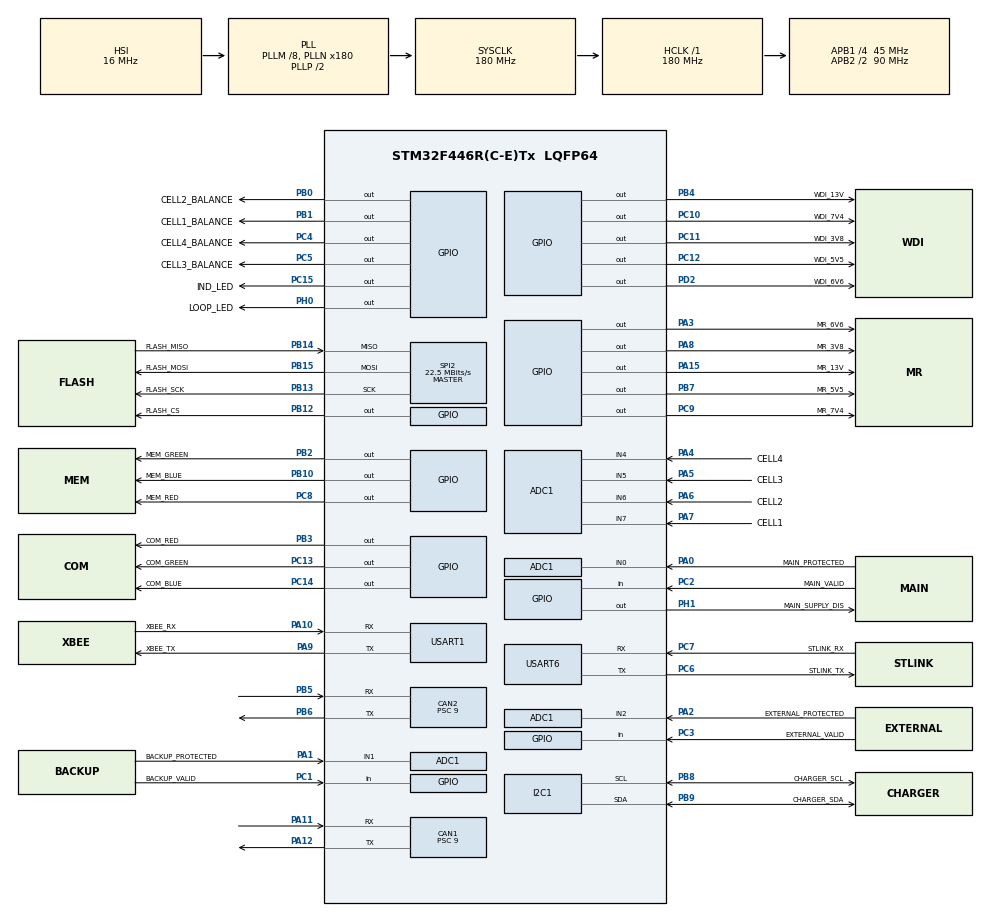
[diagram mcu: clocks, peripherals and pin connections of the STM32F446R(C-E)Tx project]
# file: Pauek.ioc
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Dma.USART1_TX.2.Direction=DMA_MEMORY_TO_PERIPH
NVIC.CAN1_RX1_IRQn=true\:5\:0\:true\:false\:true\:true\:true
PH0-OSC_IN.GPIO_PuPd=GPIO_NOPULL
PH0-OSC_IN.Signal=GPIO_Output
PC10.GPIO_PuPd=GPIO_NOPULL
PH0-OSC_IN.PinState=GPIO_PIN_RESET
PB10.GPIO_PuPd=GPIO_NOPULL
SPI2.VirtualType=VM_MASTER
PA10.GPIO_PuPd=GPIO_PULLUP
ADC1.SamplingTime-6\#ChannelRegularConversion=ADC_SAMPLETIME_56CYCLES
PC12.Signal=GPIO_Output
PB14.GPIO_Label=FLASH_MISO
PA3.GPIO_PuPd=GPIO_NOPULL
PC6.GPIO_Label=STLINK_TX
PA6.GPIO_Label=CELL2
PA3.GPIO_Speed=GPIO_SPEED_FREQ_LOW
PB13.Signal=SPI2_SCK
PC15-OSC32_OUT.GPIO_Label=IND_LED
PB3.GPIO_Speed=GPIO_SPEED_FREQ_LOW
RCC.SYSCLKSource=RCC_SYSCLKSOURCE_PLLCLK
PA6.GPIO_Mode=GPIO_MODE_ANALOG
ADC1.Channel-5\#ChannelRegularConversion=ADC_CHANNEL_6
PC13.GPIO_ModeDefaultOutputPP=GPIO_MODE_OUTPUT_PP
PB3.PinState=GPIO_PIN_RESET
NVIC.CAN1_TX_IRQn=true\:5\:0\:true\:false\:true\:true\:true
RCC.APB2TimFreq_Value=180000000
PB6.Signal=CAN2_TX
Dma.ADC1.0.Direction=DMA_PERIPH_TO_MEMORY
ADC1.Channel-2\#ChannelRegularConversion=ADC_CHANNEL_2
PC7.Signal=USART6_RX
ADC1.InjNumberOfConversion=0
PB12.PinState=GPIO_PIN_RESET
PB6.Mode=Slave
PC3.Signal=GPIO_Input
PA1.GPIO_PuPd=GPIO_NOPULL
Dma.ADC1.0.MemDataAlignment=DMA_MDATAALIGN_HALFWORD
Dma.USART1_RX.1.PeriphDataAlignment=DMA_PDATAALIGN_BYTE
NVIC.TIM8_TRG_COM_TIM14_IRQn=true\:5\:0\:true\:false\:true\:true\:true
PB2.Signal=GPIO_Output
PB12.GPIO_ModeDefaultOutputPP=GPIO_MODE_OUTPUT_PP
PC1.GPIO_PuPd=GPIO_NOPULL
PB12.GPIO_Label=FLASH_CS
PC4.GPIO_Label=CELL4_BALANCE
PB1.GPIO_Speed=GPIO_SPEED_FREQ_LOW
PB14.Mode=Full_Duplex_Master
PA5.GPIO_PuPd=GPIO_NOPULL
PB1.GPIO_Label=CELL1_BALANCE
Dma.ADC1.0.PeriphInc=DMA_PINC_DISABLE
PA0-WKUP.GPIO_Mode=GPIO_MODE_ANALOG
SPI2.CalculateBaudRate=22.5 MBits/s
PC11.GPIO_Speed=GPIO_SPEED_FREQ_LOW
PA8.Signal=GPIO_Output
PA8.GPIO_ModeDefaultOutputPP=GPIO_MODE_OUTPUT_OD
PC15-OSC32_OUT.PinState=GPIO_PIN_RESET
PC10.PinState=GPIO_PIN_RESET
Dma.USART1_TX.2.MemDataAlignment=DMA_MDATAALIGN_BYTE
PB2.GPIO_PuPd=GPIO_NOPULL
ADC1.SamplingTime-0\#ChannelRegularConversion=ADC_SAMPLETIME_56CYCLES
PB7.PinState=GPIO_PIN_SET
PC14-OSC32_IN.GPIO_Speed=GPIO_SPEED_FREQ_LOW
Dma.USART1_RX.1.Mode=DMA_NORMAL
PC10.GPIO_ModeDefaultOutputPP=GPIO_MODE_OUTPUT_PP
CAN1.Prescaler=9
Mcu.Package=LQFP64
PB9.Signal=I2C1_SDA
PB1.Signal=GPIO_Output
NVIC.TimeBase=TIM8_UP_TIM13_IRQn
SPI2.Mode=SPI_MODE_MASTER
NVIC.TimeBaseIP=TIM13
PA10.Signal=USART1_RX
PC6.GPIO_PuPd=GPIO_PULLUP
PC8.GPIO_Speed=GPIO_SPEED_FREQ_LOW
Dma.USART1_RX.1.PeriphInc=DMA_PINC_DISABLE
RCC.APB2CLKDivider=RCC_HCLK_DIV2
NVIC.DMA2_Stream2_IRQn=true\:5\:0\:true\:false\:true\:false\:true
PC2.GPIO_Mode=GPIO_MODE_INPUT
RCC.APB1TimFreq_Value=90000000
Dma.ADC1.0.FIFOMode=DMA_FIFOMODE_DISABLE
PB0.GPIO_ModeDefaultOutputPP=GPIO_MODE_OUTPUT_PP
PB13.Mode=Full_Duplex_Master
VP_TIM14_VS_ClockSourceINT.Mode=Enable_Timer
PC12.GPIO_PuPd=GPIO_NOPULL
NVIC.USART1_IRQn=true\:5\:0\:true\:false\:true\:true\:true
PB2.GPIO_ModeDefaultOutputPP=GPIO_MODE_OUTPUT_PP
PA4.GPIO_Label=CELL4
PC6.GPIO_Speed=GPIO_SPEED_FREQ_VERY_HIGH
PA8.GPIO_Speed=GPIO_SPEED_FREQ_LOW
ADC1.EOCSelection=ADC_EOC_SEQ_CONV
ADC1.Rank-4\#ChannelRegularConversion=5
CAN1.CalculateTimeQuantum=200.0
PA2.GPIO_Mode=GPIO_MODE_ANALOG
PB7.GPIO_PuPd=GPIO_NOPULL
Dma.USART1_RX.1.Instance=DMA2_Stream2
NVIC.CAN2_TX_IRQn=true\:5\:0\:true\:false\:true\:true\:true
Dma.ADC1.0.Instance=DMA2_Stream0
PA3.GPIO_ModeDefaultOutputPP=GPIO_MODE_OUTPUT_OD
Dma.USART1_RX.1.MemDataAlignment=DMA_MDATAALIGN_BYTE
ADC1.Rank-0\#ChannelRegularConversion=1
Dma.USART1_TX.2.MemInc=DMA_MINC_ENABLE
PA1.GPIO_Mode=GPIO_MODE_ANALOG
PC4.PinState=GPIO_PIN_RESET
PD2.GPIO_PuPd=GPIO_NOPULL
SH.ADCx_IN6.0=ADC1_IN6,IN6
PA9.GPIO_Label=XBEE_TX
PC13.Signal=GPIO_Output
PC2.Signal=GPIO_Input
PC6.Signal=USART6_TX
PC9.PinState=GPIO_PIN_SET
PC12.GPIO_ModeDefaultOutputPP=GPIO_MODE_OUTPUT_PP
RCC.APB1CLKDivider=RCC_HCLK_DIV4
PC14-OSC32_IN.Signal=GPIO_Output
NVIC.CAN2_RX1_IRQn=true\:5\:0\:true\:false\:true\:true\:true
PA0-WKUP.GPIO_Label=MAIN_PROTECTED
PA0-WKUP.Signal=ADCx_IN0
PB8.GPIO_Label=CHARGER_SCL
PA8.GPIO_Label=MR_3V8
PC12.PinState=GPIO_PIN_RESET
SH.ADCx_IN7.0=ADC1_IN7,IN7
PC6.Mode=Asynchronous
Dma.ADC1.0.Priority=DMA_PRIORITY_LOW
PA9.Signal=USART1_TX
VP_TIM8_VS_ClockSourceINT.Mode=Internal
PB4.GPIO_PuPd=GPIO_NOPULL
PC7.GPIO_PuPd=GPIO_PULLUP
PH1-OSC_OUT.GPIO_PuPd=GPIO_NOPULL
PB10.Signal=GPIO_Output
PB14.Signal=SPI2_MISO
PA5.Signal=ADCx_IN5
Dma.USART1_RX.1.FIFOMode=DMA_FIFOMODE_DISABLE
Dma.USART1_TX.2.FIFOMode=DMA_FIFOMODE_DISABLE
PB4.GPIO_Label=WDI_13V
PB15.GPIO_Label=FLASH_MOSI
PA1.GPIO_Label=BACKUP_PROTECTED
PC9.GPIO_PuPd=GPIO_NOPULL
SH.ADCx_IN4.0=ADC1_IN4,IN4
PC15-OSC32_OUT.GPIO_PuPd=GPIO_NOPULL
PH1-OSC_OUT.GPIO_Label=MAIN_SUPPLY_DIS
PC6.GPIO_Mode=GPIO_MODE_AF_PP
PC11.GPIO_ModeDefaultOutputPP=GPIO_MODE_OUTPUT_PP
ADC1.DMAContinuousRequests=ENABLE
PA13.Mode=Serial_Wire
TIM14.Prescaler=8900
ADC1.ExternalTrigConv=ADC_EXTERNALTRIGCONV_T8_TRGO
TIM8.Period=999
PC7.GPIO_Label=STLINK_RX
PC8.GPIO_PuPd=GPIO_NOPULL
PA4.Signal=ADCx_IN4
ADC1.SamplingTime-1\#ChannelRegularConversion=ADC_SAMPLETIME_56CYCLES
PB5.Signal=CAN2_RX
ADC1.master=1
PA5.GPIO_Label=CELL3
TIM8.TIM_MasterOutputTrigger=TIM_TRGO_UPDATE
PC12.GPIO_Label=WDI_5V5
USART1.VirtualMode=VM_ASYNC
ADC1.Rank-1\#ChannelRegularConversion=2
PA11.Signal=CAN1_RX
ProjectManager.HeapSize=0x200
NVIC.CAN2_SCE_IRQn=true\:5\:0\:true\:false\:true\:true\:true
ADC1.SamplingTime-5\#ChannelRegularConversion=ADC_SAMPLETIME_56CYCLES
NVIC.TIM8_UP_TIM13_IRQn=true\:0\:0\:true\:false\:true\:false\:true
PH1-OSC_OUT.PinState=GPIO_PIN_RESET
SH.ADCx_IN5.0=ADC1_IN5,IN5
PC9.GPIO_Speed=GPIO_SPEED_FREQ_LOW
NVIC.PriorityGroup=NVIC_PRIORITYGROUP_4
PC5.GPIO_Speed=GPIO_SPEED_FREQ_LOW
Dma.USART1_TX.2.Instance=DMA2_Stream7
PB8.Mode=I2C
PC3.GPIO_Label=EXTERNAL_VALID
PA0-WKUP.GPIO_PuPd=GPIO_NOPULL
PA3.PinState=GPIO_PIN_SET
PC14-OSC32_IN.GPIO_PuPd=GPIO_NOPULL
Dma.USART1_RX.1.Direction=DMA_PERIPH_TO_MEMORY
PB1.GPIO_ModeDefaultOutputPP=GPIO_MODE_OUTPUT_PP
PD2.Signal=GPIO_Output
PB12.GPIO_PuPd=GPIO_NOPULL
PB0.Signal=GPIO_Output
ADC1.Rank-5\#ChannelRegularConversion=6
PC1.Signal=GPIO_Input
PD2.GPIO_Label=WDI_6V6
NVIC.CAN1_RX0_IRQn=true\:5\:0\:true\:false\:true\:true\:true
Mcu.Family=STM32F4
PC3.GPIO_Mode=GPIO_MODE_INPUT
PA2.GPIO_PuPd=GPIO_NOPULL
PB10.PinState=GPIO_PIN_RESET
RCC.CortexFreq_Value=180000000
PD2.GPIO_ModeDefaultOutputPP=GPIO_MODE_OUTPUT_PP
NVIC.CAN2_RX0_IRQn=true\:5\:0\:true\:false\:true\:true\:true
PB10.GPIO_Speed=GPIO_SPEED_FREQ_LOW
ADC1.ContinuousConvMode=DISABLE
SH.ADCx_IN2.0=ADC1_IN2,IN2
PC10.Signal=GPIO_Output
PB2.GPIO_Speed=GPIO_SPEED_FREQ_LOW
PA7.GPIO_Mode=GPIO_MODE_ANALOG
PA11.Mode=Master
PD2.GPIO_Speed=GPIO_SPEED_FREQ_LOW
PB0.GPIO_Label=CELL2_BALANCE
PC10.GPIO_Speed=GPIO_SPEED_FREQ_LOW
PC13.GPIO_Label=COM_GREEN
PB13.GPIO_Label=FLASH_SCK
PB15.Signal=SPI2_MOSI
ProjectManager.StackSize=0x400
PC8.PinState=GPIO_PIN_RESET
PH1-OSC_OUT.GPIO_Speed=GPIO_SPEED_FREQ_LOW
PH1-OSC_OUT.GPIO_ModeDefaultOutputPP=GPIO_MODE_OUTPUT_PP
NVIC.ADC_IRQn=true\:5\:0\:true\:false\:true\:true\:true
PA15.GPIO_Label=MR_13V
PC11.GPIO_PuPd=GPIO_NOPULL
PB10.GPIO_ModeDefaultOutputPP=GPIO_MODE_OUTPUT_PP
PA12.Signal=CAN1_TX
PB0.PinState=GPIO_PIN_RESET
ADC1.Channel-3\#ChannelRegularConversion=ADC_CHANNEL_4
PB1.GPIO_PuPd=GPIO_NOPULL
RCC.HCLKFreq_Value=180000000
PH0-OSC_IN.GPIO_ModeDefaultOutputPP=GPIO_MODE_OUTPUT_PP
NVIC.DMA2_Stream0_IRQn=true\:5\:0\:true\:false\:true\:false\:true
NVIC.CAN1_SCE_IRQn=true\:5\:0\:true\:false\:true\:true\:true
Dma.USART1_RX.1.MemInc=DMA_MINC_ENABLE
RCC.AHBFreq_Value=180000000
PH0-OSC_IN.GPIO_Label=LOOP_LED
PA9.GPIO_Mode=GPIO_MODE_AF_PP
PC1.GPIO_Mode=GPIO_MODE_INPUT
ADC1.Channel-0\#ChannelRegularConversion=ADC_CHANNEL_0
PA4.GPIO_PuPd=GPIO_NOPULL
PC4.GPIO_Speed=GPIO_SPEED_FREQ_LOW
ADC1.SamplingTime-4\#ChannelRegularConversion=ADC_SAMPLETIME_56CYCLES
ADC1.Channel-6\#ChannelRegularConversion=ADC_CHANNEL_7
PA6.GPIO_PuPd=GPIO_NOPULL
PB3.GPIO_PuPd=GPIO_NOPULL
ADC1.Rank-2\#ChannelRegularConversion=3
PA14.Mode=Serial_Wire
CAN2.Prescaler=9
PC11.GPIO_Label=WDI_3V8
PB5.Mode=Slave
PA10.GPIO_Label=XBEE_RX
PC13.GPIO_PuPd=GPIO_NOPULL
PC7.GPIO_Mode=GPIO_MODE_AF_PP
Dma.USART1_TX.2.PeriphDataAlignment=DMA_PDATAALIGN_BYTE
PB7.Signal=GPIO_Output
SH.ADCx_IN0.0=ADC1_IN0,IN0
PA15.GPIO_ModeDefaultOutputPP=GPIO_MODE_OUTPUT_OD
PB1.PinState=GPIO_PIN_RESET
PB7.GPIO_Label=MR_5V5
PA6.Signal=ADCx_IN6
NVIC.DMA2_Stream7_IRQn=true\:5\:0\:true\:false\:true\:false\:true
CAN2.BS1=CAN_BS1_6TQ
CAN2.BS2=CAN_BS2_6TQ
PC14-OSC32_IN.PinState=GPIO_PIN_RESET
USART6.VirtualMode=VM_ASYNC
PA2.GPIO_Label=EXTERNAL_PROTECTED
PC8.GPIO_ModeDefaultOutputPP=GPIO_MODE_OUTPUT_PP
PA15.Signal=GPIO_Output
PA10.GPIO_Speed=GPIO_SPEED_FREQ_VERY_HIGH
TIM8.Prescaler=8999
SH.ADCx_IN1.0=ADC1_IN1,IN1
PC15-OSC32_OUT.GPIO_ModeDefaultOutputPP=GPIO_MODE_OUTPUT_PP
Dma.Request2=USART1_TX
PC14-OSC32_IN.GPIO_ModeDefaultOutputPP=GPIO_MODE_OUTPUT_PP
Dma.Request1=USART1_RX
PC13.GPIO_Speed=GPIO_SPEED_FREQ_LOW
PC14-OSC32_IN.GPIO_Label=COM_BLUE
SPI2.Direction=SPI_DIRECTION_2LINES
PC15-OSC32_OUT.GPIO_Speed=GPIO_SPEED_FREQ_LOW
PC5.Signal=GPIO_Output
Dma.USART1_RX.1.Priority=DMA_PRIORITY_LOW
PC4.GPIO_ModeDefaultOutputPP=GPIO_MODE_OUTPUT_PP
ADC1.Rank-6\#ChannelRegularConversion=7
Dma.Request0=ADC1
PB4.PinState=GPIO_PIN_RESET
PC2.GPIO_Label=MAIN_VALID
PC13.PinState=GPIO_PIN_RESET
PA8.PinState=GPIO_PIN_SET
PB4.Signal=GPIO_Output
PB4.GPIO_ModeDefaultOutputPP=GPIO_MODE_OUTPUT_PP
PA3.Signal=GPIO_Output
PB7.GPIO_Speed=GPIO_SPEED_FREQ_LOW
PB3.GPIO_Label=COM_RED
PB9.GPIO_Label=CHARGER_SDA
ADC1.Channel-4\#ChannelRegularConversion=ADC_CHANNEL_5
PA10.Mode=Asynchronous
PC10.GPIO_Label=WDI_7V4
PC9.GPIO_Label=MR_7V4
PC4.GPIO_PuPd=GPIO_NOPULL
PC11.Signal=GPIO_Output
PC8.Signal=GPIO_Output
PC4.Signal=GPIO_Output
PC5.GPIO_PuPd=GPIO_NOPULL
PA9.GPIO_PuPd=GPIO_PULLUP
ADC1.SamplingTime-2\#ChannelRegularConversion=ADC_SAMPLETIME_56CYCLES
NVIC.USART6_IRQn=true\:5\:0\:true\:false\:true\:true\:true
PA10.GPIO_Mode=GPIO_MODE_AF_PP
PB0.GPIO_Speed=GPIO_SPEED_FREQ_LOW
PC8.GPIO_Label=MEM_RED
PA13.Signal=SYS_JTMS-SWDIO
Dma.ADC1.0.PeriphDataAlignment=DMA_PDATAALIGN_HALFWORD
PA9.Mode=Asynchronous
CAN1.BS2=CAN_BS2_6TQ
CAN1.BS1=CAN_BS1_6TQ
ProjectManager.TargetToolchain=SW4STM32
PB10.GPIO_Label=MEM_BLUE
Dma.ADC1.0.Mode=DMA_CIRCULAR
PB9.Mode=I2C
ADC1.Channel-1\#ChannelRegularConversion=ADC_CHANNEL_1
RCC.USBFreq_Value=180000000
PC15-OSC32_OUT.Signal=GPIO_Output
PA1.Signal=ADCx_IN1
PA7.GPIO_PuPd=GPIO_NOPULL
PB12.GPIO_Speed=GPIO_SPEED_FREQ_LOW
PD2.PinState=GPIO_PIN_RESET
board=custom
PC7.GPIO_Speed=GPIO_SPEED_FREQ_VERY_HIGH
RCC.VCOOutputFreq_Value=360000000
PB15.Mode=Full_Duplex_Master
PA4.GPIO_Mode=GPIO_MODE_ANALOG
PA15.PinState=GPIO_PIN_SET
PB4.GPIO_Speed=GPIO_SPEED_FREQ_LOW
RCC.APB2Freq_Value=90000000
PC11.PinState=GPIO_PIN_RESET
VP_SYS_VS_tim13.Mode=TIM13
PB7.GPIO_ModeDefaultOutputPP=GPIO_MODE_OUTPUT_OD
PC9.GPIO_ModeDefaultOutputPP=GPIO_MODE_OUTPUT_OD
Dma.USART1_TX.2.Priority=DMA_PRIORITY_LOW
PC1.GPIO_Label=BACKUP_VALID
CAN2.CalculateTimeQuantum=200.0
PH1-OSC_OUT.Signal=GPIO_Output
PC2.GPIO_PuPd=GPIO_NOPULL
ADC1.NbrOfConversion=7
Mcu.Name=STM32F446R(C-E)Tx
PB2.PinState=GPIO_PIN_RESET
PA2.Signal=ADCx_IN2
Dma.USART1_TX.2.PeriphInc=DMA_PINC_DISABLE
PB3.Signal=GPIO_Output
RCC.SYSCLKFreq_VALUE=180000000
PA7.GPIO_Label=CELL1
PH0-OSC_IN.GPIO_Speed=GPIO_SPEED_FREQ_LOW
PC5.PinState=GPIO_PIN_RESET
PA12.Mode=Master
ADC1.Rank-3\#ChannelRegularConversion=4
ADC1.SamplingTime-3\#ChannelRegularConversion=ADC_SAMPLETIME_56CYCLES
PC5.GPIO_Label=CELL3_BALANCE
PA15.GPIO_Speed=GPIO_SPEED_FREQ_LOW
PA14.Signal=SYS_JTCK-SWCLK
Dma.ADC1.0.MemInc=DMA_MINC_ENABLE
PB2.GPIO_Label=MEM_GREEN
Dma.USART1_TX.2.Mode=DMA_NORMAL
PA8.GPIO_PuPd=GPIO_NOPULL
ADC1.NbrOfConversionFlag=1
RCC.PLLM=8
RCC.PLLN=180
PA15.GPIO_PuPd=GPIO_NOPULL
PA9.GPIO_Speed=GPIO_SPEED_FREQ_VERY_HIGH
PB8.Signal=I2C1_SCL
PC9.Signal=GPIO_Output
PC7.Mode=Asynchronous
RCC.APB1Freq_Value=45000000
PA5.GPIO_Mode=GPIO_MODE_ANALOG
PC12.GPIO_Speed=GPIO_SPEED_FREQ_LOW
VP_CRC_VS_CRC.Mode=CRC_Activate
PC5.GPIO_ModeDefaultOutputPP=GPIO_MODE_OUTPUT_PP
PB12.Signal=GPIO_Output
PB0.GPIO_PuPd=GPIO_NOPULL
PC3.GPIO_PuPd=GPIO_NOPULL
PB3.GPIO_ModeDefaultOutputPP=GPIO_MODE_OUTPUT_PP
PA3.GPIO_Label=MR_6V6
PA7.Signal=ADCx_IN7

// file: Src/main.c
/* USER CODE BEGIN Header */
/**
  ******************************************************************************
  * @file           : main.c
  * @brief          : Main program body
  ******************************************************************************
  * @attention
  *
  * <h2><center>&copy; Copyright (c) 2020 STMicroelectronics.
  * All rights reserved.</center></h2>
  *
  * This software component is licensed by ST under BSD 3-Clause license,
  * the "License"; You may not use this file except in compliance with the
  * License. You may obtain a copy of the License at:
  *                        opensource.org/licenses/BSD-3-Clause
  *
  ******************************************************************************
  */
/* USER CODE END Header */

#include "main.h"

#include "adc.h"
#include "can.h"
#include "crc.h"
#include "dma.h"
#include "gpio.h"
#include "i2c.h"
#include "spi.h"
#include "tim.h"
#include "usart.h"

/* USER CODE BEGIN Includes */
#include "SS_com.h"
#include "SS_common.h"
#include "SS_log.h"
#include "SS_platform.h"
/* USER CODE END Includes */

void SystemClock_Config(void);

int main(void) {

    /* MCU Configuration--------------------------------------------------------*/

    /* Reset of all peripherals, Initializes the Flash interface and the Systick. */
    HAL_Init();

    /* Configure the system clock */
    SystemClock_Config();

    /* Initialize all configured peripherals */
    MX_GPIO_Init();
    MX_DMA_Init();
    MX_ADC1_Init();
    MX_CAN1_Init();
    MX_CAN2_Init();
    MX_CRC_Init();
    MX_I2C1_Init();
    MX_SPI2_Init();
    MX_USART1_UART_Init();
    MX_USART6_UART_Init();
    MX_TIM8_Init();
    MX_TIM14_Init();
    /* USER CODE BEGIN 2 */

    SS_platform_init();
    SS_init();
    /* USER CODE END 2 */

    /* Infinite loop */
    while(1) {

    }
}

void SystemClock_Config(void) {
    RCC_OscInitTypeDef RCC_OscInitStruct = {0};
    RCC_ClkInitTypeDef RCC_ClkInitStruct = {0};

    /** Configure the main internal regulator output voltage
  */
    __HAL_RCC_PWR_CLK_ENABLE();
    __HAL_PWR_VOLTAGESCALING_CONFIG(PWR_REGULATOR_VOLTAGE_SCALE1);
    /** Initializes the CPU, AHB and APB busses clocks
  */
    RCC_OscInitStruct.OscillatorType = RCC_OSCILLATORTYPE_HSI;
    RCC_OscInitStruct.HSIState = RCC_HSI_ON;
    RCC_OscInitStruct.HSICalibrationValue = RCC_HSICALIBRATION_DEFAULT;
    RCC_OscInitStruct.PLL.PLLState = RCC_PLL_ON;
    RCC_OscInitStruct.PLL.PLLSource = RCC_PLLSOURCE_HSI;
    RCC_OscInitStruct.PLL.PLLM = 8;
    RCC_OscInitStruct.PLL.PLLN = 180;
    RCC_OscInitStruct.PLL.PLLP = RCC_PLLP_DIV2;
    RCC_OscInitStruct.PLL.PLLQ = 2;
    RCC_OscInitStruct.PLL.PLLR = 2;
    if(HAL_RCC_OscConfig(&RCC_OscInitStruct) != HAL_OK) {
        Error_Handler();
    }
    /** Activate the Over-Drive mode
  */
    if(HAL_PWREx_EnableOverDrive() != HAL_OK) {
        Error_Handler();
    }
    /** Initializes the CPU, AHB and APB busses clocks
  */
    RCC_ClkInitStruct.ClockType = RCC_CLOCKTYPE_HCLK | RCC_CLOCKTYPE_SYSCLK | RCC_CLOCKTYPE_PCLK1 | RCC_CLOCKTYPE_PCLK2;
    RCC_ClkInitStruct.SYSCLKSource = RCC_SYSCLKSOURCE_PLLCLK;
    RCC_ClkInitStruct.AHBCLKDivider = RCC_SYSCLK_DIV1;
    RCC_ClkInitStruct.APB1CLKDivider = RCC_HCLK_DIV4;
    RCC_ClkInitStruct.APB2CLKDivider = RCC_HCLK_DIV2;

    if(HAL_RCC_ClockConfig(&RCC_ClkInitStruct, FLASH_LATENCY_5) != HAL_OK) {
        Error_Handler();
    }
}

void HAL_TIM_PeriodElapsedCallback(TIM_HandleTypeDef *htim) {
    if(htim->Instance == TIM13) {
        HAL_IncTick();
    }
}

void Error_Handler(void) {
    /* USER CODE BEGIN Error_Handler_Debug */
    /* User can add his own implementation to report the HAL error return state */
    SS_error("Hal error");

    /* USER CODE END Error_Handler_Debug */
}

/************************ (C) COPYRIGHT STMicroelectronics *****END OF FILE****/
